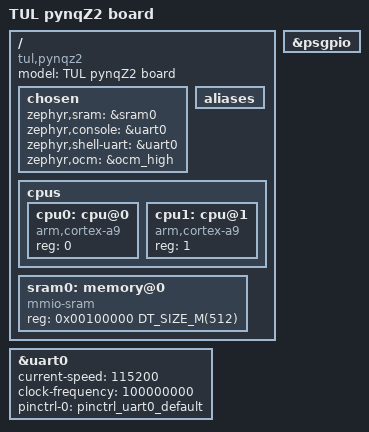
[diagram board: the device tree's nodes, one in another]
/*
 * Copyright (c) 2026 nalexopo
 *
 * SPDX-License-Identifier: Apache-2.0
 */

/dts-v1/;
#include <xilinx/zynq7000.dtsi>
#include <zephyr/dt-bindings/gpio/gpio.h>
#include <zephyr/dt-bindings/input/input-event-codes.h>

#include "pynqz2-pinctrl.dtsi"

/ {
	model = "TUL pynqZ2 board";
	compatible = "tul,pynqz2", "xlnx,zynq-7000";

	chosen {
		zephyr,sram = &sram0;
		zephyr,console = &uart0;
		zephyr,shell-uart = &uart0;
		zephyr,ocm = &ocm_high;
	};

	aliases {

	};

	cpus {
		#address-cells = <1>;
		#size-cells = <0>;

		cpu0: cpu@0 {
			device_type = "cpu";
			compatible = "arm,cortex-a9";
			reg = <0>;
		};

		cpu1: cpu@1 {
			device_type = "cpu";
			compatible = "arm,cortex-a9";
			reg = <1>;
		};
	};

	sram0: memory@0 {
		compatible = "mmio-sram";
		reg = <0x00100000 DT_SIZE_M(512)>;
	};

};

&uart0 {
	status = "okay";
	current-speed = <115200>;
	clock-frequency = <100000000>;
	pinctrl-0 = <&pinctrl_uart0_default>;
	pinctrl-names = "default";
};

&psgpio {
	status = "okay";
};
